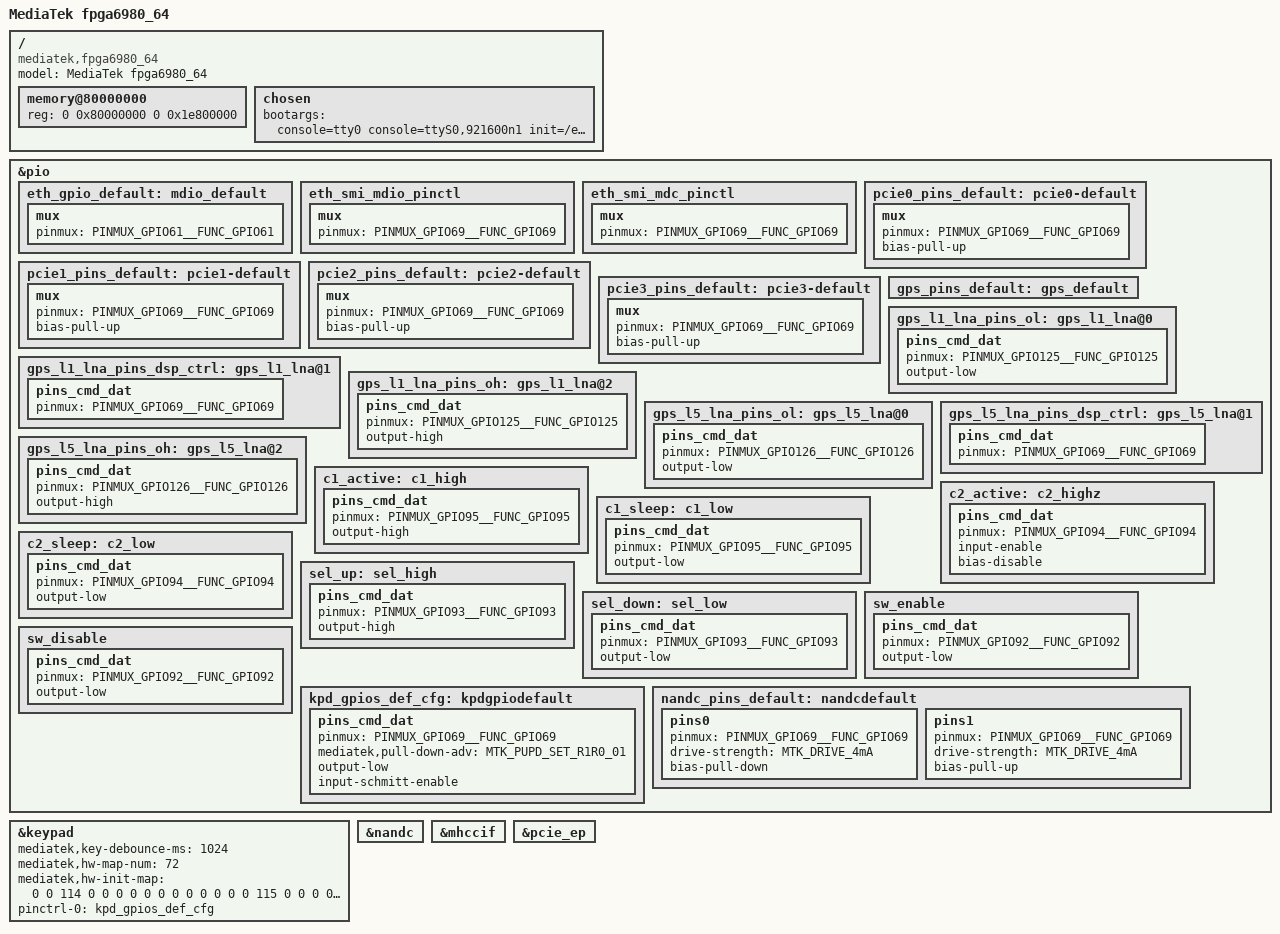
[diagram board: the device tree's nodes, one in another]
// SPDX-License-Identifier: GPL-2.0
/*
 * Copyright (c) 2019 MediaTek Inc.
 */

/dts-v1/;
#include <dt-bindings/interrupt-controller/irq.h>
#include <dt-bindings/interrupt-controller/arm-gic.h>
#include "mt6980.dtsi"


/ {
	model = "MediaTek fpga6980_64";
	compatible = "mediatek,fpga6980_64", "mediatek,mt6980";

	memory@80000000 {
		device_type = "memory";
		reg = <0 0x80000000 0 0x1e800000>;
	};

	chosen {
		bootargs = "console=tty0 console=ttyS0,921600n1 \
		init=/etc/preinit root=/dev/ubiblock0_0 rootfstype=squashfs ubi.mtd=19 \
		androidboot.selinux=permissive androidboot.hardware=mt6980 \
		earlycon=mtk8250,mmio32,0x11002000 \
		mtk_printk_ctrl.disable_uart=0";
	};

};

/* GPS GPIO standardization start */
#if 1
&pio {

	eth_gpio_default: mdio_default {
		mux {
			pinmux = <PINMUX_GPIO61__FUNC_GPIO61>;
		};
	};

	eth_smi_mdio_pinctl: eth_smi_mdio_pinctl {
		mux {
			pinmux = <PINMUX_GPIO69__FUNC_GPIO69>;
		};
	};

	eth_smi_mdc_pinctl: eth_smi_mdc_pinctl {
		mux {
			pinmux = <PINMUX_GPIO69__FUNC_GPIO69>;
		};
	};

	pcie0_pins_default: pcie0-default {
		mux {
			pinmux = <PINMUX_GPIO69__FUNC_GPIO69>;
			bias-pull-up;
		};
	};

	pcie1_pins_default: pcie1-default {
		mux {
			pinmux = <PINMUX_GPIO69__FUNC_GPIO69>;
			bias-pull-up;
		};
	};

	pcie2_pins_default: pcie2-default {
		mux {
			pinmux = <PINMUX_GPIO69__FUNC_GPIO69>;
			bias-pull-up;
		};
	};

	pcie3_pins_default: pcie3-default {
		mux {
			pinmux = <PINMUX_GPIO69__FUNC_GPIO69>;
			bias-pull-up;
		};
	};

	gps_pins_default: gps_default {
	};

	gps_l1_lna_pins_ol: gps_l1_lna@0 {
		pins_cmd_dat {
			pinmux = <PINMUX_GPIO125__FUNC_GPIO125>;
			output-low;
		};
	};
	gps_l1_lna_pins_dsp_ctrl: gps_l1_lna@1 {
		pins_cmd_dat {
			pinmux = <PINMUX_GPIO69__FUNC_GPIO69>;
		};
	};
	gps_l1_lna_pins_oh: gps_l1_lna@2 {
		pins_cmd_dat {
			pinmux = <PINMUX_GPIO125__FUNC_GPIO125>;
			output-high;
		};
	};

	gps_l5_lna_pins_ol: gps_l5_lna@0 {
		pins_cmd_dat {
			pinmux = <PINMUX_GPIO126__FUNC_GPIO126>;
			output-low;
		};
	};
	gps_l5_lna_pins_dsp_ctrl: gps_l5_lna@1 {
		pins_cmd_dat {
			pinmux = <PINMUX_GPIO69__FUNC_GPIO69>;
		};
	};
	gps_l5_lna_pins_oh: gps_l5_lna@2 {
		pins_cmd_dat {
			pinmux = <PINMUX_GPIO126__FUNC_GPIO126>;
			output-high;
		};
	};
};

#endif
/* GPS GPIO standardization end */

/* usb typec swtich */
&pio {
	c1_active: c1_high {
		pins_cmd_dat {
			pinmux = <PINMUX_GPIO95__FUNC_GPIO95>;
			output-high;
		};
	};

	c2_active: c2_highz {
		pins_cmd_dat {
			pinmux = <PINMUX_GPIO94__FUNC_GPIO94>;
			input-enable;
			bias-disable;
		};
	};

	c1_sleep: c1_low {
		pins_cmd_dat {
			pinmux = <PINMUX_GPIO95__FUNC_GPIO95>;
			output-low;
		};
	};

	c2_sleep: c2_low {
		pins_cmd_dat {
			pinmux = <PINMUX_GPIO94__FUNC_GPIO94>;
			output-low;
		};
	};

	sel_up: sel_high {
		pins_cmd_dat {
			pinmux = <PINMUX_GPIO93__FUNC_GPIO93>;
			output-high;
		};
	};

	sel_down: sel_low {
		pins_cmd_dat {
			pinmux = <PINMUX_GPIO93__FUNC_GPIO93>;
			output-low;
		};
	};

	sw_enable: sw_enable {
		pins_cmd_dat {
			pinmux = <PINMUX_GPIO92__FUNC_GPIO92>;
			output-low;
		};
	};

	sw_disable: sw_disable {
		pins_cmd_dat {
			pinmux = <PINMUX_GPIO92__FUNC_GPIO92>;
			output-low;
		};
	};
	kpd_gpios_def_cfg: kpdgpiodefault {
		pins_cmd_dat {
			pinmux = <PINMUX_GPIO69__FUNC_GPIO69>;
			mediatek,pull-down-adv = <MTK_PUPD_SET_R1R0_01>;
			output-low;
			input-schmitt-enable;
		};
	};
};

&keypad {
	mediatek,key-debounce-ms = <1024>;
	/*HW Keycode [0~71] -> Linux Keycode*/
	mediatek,hw-map-num = <72>;
	mediatek,hw-init-map = <0 0 114 0 0 0 0 0 0 0 0 0 0 0 0 115 0 0 0 0 0 0 0
		0 0 0 0 0 112 0 0 0 0 0 0 0 0 0 0 0 0 0 0 0 0 0 0 0 0 0 0 0 0 0 0
		0 0 0 0 0 0 0 0 0 0 0 0 0 0 0 0 0 >;
	status = "okay";
	pinctrl-names = "default";
	pinctrl-0 = <&kpd_gpios_def_cfg>;
};

&pio {
	nandc_pins_default: nandcdefault {
		pins0 {
			pinmux = <PINMUX_GPIO69__FUNC_GPIO69>;
			drive-strength = <MTK_DRIVE_4mA>;
			bias-pull-down;
		};
		pins1 {
			pinmux = <PINMUX_GPIO69__FUNC_GPIO69>;
			drive-strength = <MTK_DRIVE_4mA>;
			bias-pull-up;
		};
	};
};

&nandc {
	status = "okay";
};

&mhccif {
	status = "okay";
};

&pcie_ep {
	status = "okay";
};
/*End of this file, DO NOT ADD ANYTHING HERE*/
